# AC7840x register map
Vendor: AutoChips; Series: AC78; File version: 1.0
CPU: CM4 r0p1, little endian, MPU, FPU, VTOR, 4 interrupt priority bits
Registers are 32-bit, read-write, reset 0x0 unless marked. A register's access mark holds for its fields unless they carry their own. Offsets are from the block's base; [hi:lo] are bit positions; lines under a group give offsets from that group; {n}, {i} and the like mark numbered series; 'fields as' and 'values as' point back to an identical list.

## ADC0 — Analog to Digital Converter
Base 0x40003000
Same registers: ADC1 0x40004000
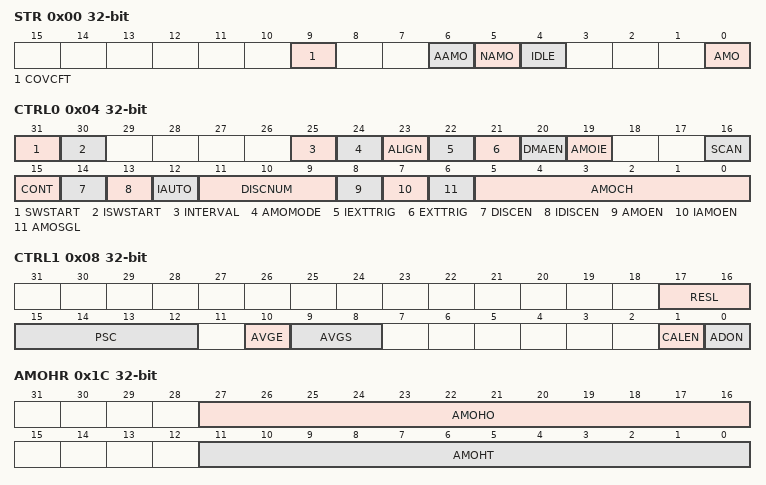
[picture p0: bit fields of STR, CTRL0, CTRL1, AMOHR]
0x00 STR — ADC status Register
  [9] COVCFT — Convert trigger confilict status
    0=No conflict; 1=Conflict occurred
  [6] AAMO — Analog monitor Abnormal event occurs(Edge mode)
    0=No analog monitor event; 1=Analog monitor abnormal event occurs
  [5] NAMO — Analog monitor normal event occurs(Edge mode)
    0=No analog monitor event; 1=Analog monitor normal event occurs
  [4] IDLE ro — ADC idle status indicate
    0=Busy status; 1=Idle status
  [0] AMO — Analog monitor event occurs(Level mode)
    0=No analog monitor event; 1=Analog monitor event occurs
0x04 CTRL0 — ADC Control Register 0
  [31] SWSTART — Software trigger for regular group
  [30] ISWSTART — Software trigger for Inject group
  [25] INTERVAL — Interval mode
    0=Normal mode; 1=Interval mode
  [24] AMOMODE — Analog monitor type
    0=Level mode; 1=Edge mode
  [23] ALIGN — Data Alignment
    0=Right Alignment; 1=Left Alignment
  [22] IEXTTRIG — Injected group trigger source select
    0=Internal trigger source; 1=External trigger source
  [21] EXTTRIG — Regular group trigger source select
    0=Internal trigger source; 1=External trigger source
  [20] DMAEN — DMA Function Enable
    0=DMA function disabled; 1=DMA function enabled
  [19] AMOIE — AMO interrupt Enable
    0=AMO interrupt disabled; 1=AMO interrupt enabled
  [16] SCAN — Scan Mode
    0=Scan mode disabled; 1=Scan mode enabled
  [15] CONT — Continuous conversion
    0=Single conversion mode; 1=Continuous conversion mode
  [14] DISCEN — Discontinous mode on regular group
    0=Regular group Discontinous mode disabled; 1=Regular group Discontinous mode enabled
  [13] IDISCEN — Discontinous mode on injected group
    0=Injected group Discontinous mode disabled; 1=Injected group Discontinous mode enabled
  [12] IAUTO — Injected Group Automatic Conversion
    0=Injected group automatic conversion disabled; 1=Injected group automatic conversion enabled
  [11:9] DISCNUM — Discontinuous conversion length of Regular Group
  [8] AMOEN — Regular Group Analog Monitor Detect function Enable
  [7] IAMOEN — Injected Group Analog Monitor Detect function Enable
  [6] AMOSGL — Analog monitor detecting channel
    0=AMO used in All channels; 1=AMO function used in single channel defined in AMOCH register
  [5:0] AMOCH — Analog monitor detecting channel
0x08 CTRL1 — ADC Control Register 1
  [17:16] RESL — Resolution selection
    0=12-bit resolution; 1=10-bit resolution; 2=8-bit resolution
  [15:12] PSC — Input clock prescaler
    {v}=Divide by {v+1} (v=0..15)
  [10] AVGE — Hardware Average Enable
    0=Hardware average function disabled; 1=Hardware average function enabled
  [9:8] AVGS — Hardware Average Select
    0=4 samples averaged; 1=8 samples averaged; 2=16 samples averaged; 3=32 samples averaged
  [1] CALEN — Calibration
    0=Disable Calibration; 1=Enable Calibration
  [0] ADON — ADC converter power
    0=ADC converter power off; 1=ADC converter power on
{0xC+4i} IOFR{i} (i=0..3) — ADC Injected Group Offset Register(n)
  [11:0] IOFR — Injected group offset Value
0x1C AMOHR — AMO High threshold and offset register
  [27:16] AMOHO — High offset value
  [11:0] AMOHT — AMO High threshold value
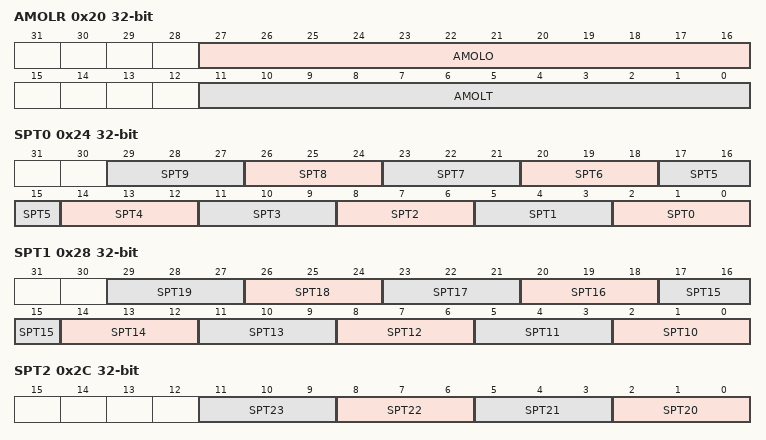
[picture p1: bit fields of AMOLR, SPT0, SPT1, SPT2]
0x20 AMOLR — AMO Low threshold and offset register
  [27:16] AMOLO — Low offset value
  [11:0] AMOLT — AMO Low threshold value
0x24 SPT0 — ADC Sample time setting register 0
  [all] fields
    0=5 ADCCLK; 1=10 ADCCLK; 2=15 ADCCLK; 3=23 ADCCLK; 4=35 ADCCLK; 5=45 ADCCLK; 6=85 ADCCLK; 7=185 ADCCLK
  [3n+2:3n] SPT{n} (n=0..9) — Sample time for channel {n}
0x28 SPT1 — ADC Sample time setting register 1
  [all] fields
    values as the fields of SPT0
  [3n-28:3n-30] SPT{n} (n=10..19) — Sample time for channel {n}
0x2C SPT2 — ADC Sample time setting register 2
  [all] fields
    values as the fields of SPT0
  [3n-58:3n-60] SPT{n} (n=20..23) — Sample time for channel {n}
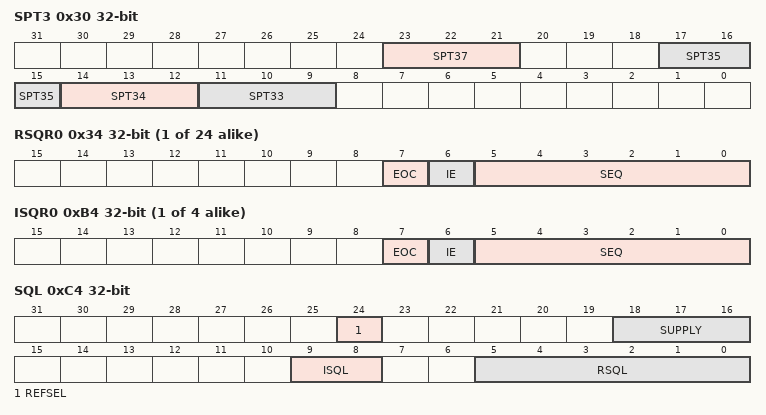
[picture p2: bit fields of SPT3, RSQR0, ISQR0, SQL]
0x30 SPT3 — ADC Sample time setting register 3
  [all] fields
    values as the fields of SPT0
  [23:21] SPT37 — Sample time for channel 37
  [17:15] SPT35 — Sample time for channel 35
  [14:12] SPT34 — Sample time for channel 34
  [11:9] SPT33 — Sample time for channel 33
{0x34+4i} RSQR{i} (i=0..23) — ADC regular group sequence configure register(n)
  [7] EOC ro — End of conversion flag
    0=Conversion is not completed; 1=Conversion is completed
  [6] IE — Interrupt enable
    0=Conversion complete interrupt is disabled; 1=Conversion complete interrupt is enabled
  [5:0] SEQ — Channel selection for regular group
    {v}=Exernal channel {v} is selected as input (v=0..23); 33=BandGap channel is selected as input; 34=T-sensor channel is selected as input; 35=GEOE calibration channel is selected as input; 37=Power supply channel is selected as input; 63=Channel disabled
{0xB4+4i} ISQR{i} (i=0..3) — ADC injected group sequence configure register(n)
  [7] EOC ro — End of conversion flag
    0=Conversion is not completed; 1=Conversion is completed
  [6] IE — Interrupt enable
    values as RSQR0.IE
  [5:0] SEQ — Channel selection for injected group
    values as RSQR0.SEQ
0xC4 SQL — Sequence length of group configure register
  [24] REFSEL — Voltage reference selection
    0=Voltage reference pin pair VREFH and VREFL; 1=Voltage reference analog supply (VDDA)
  [18:16] SUPPLY — Internal supply selection
    0=input VDD supply (VDD); 1=input analog supply (VDDA); 2=ADC Reference Supply (VREFH); 3=Oscillator Regulator Output; 4=Flash regulator output; 5=Digital regulator output
  [9:8] ISQL — Sequence length of injected group
  [5:0] RSQL — Sequence length of regular group
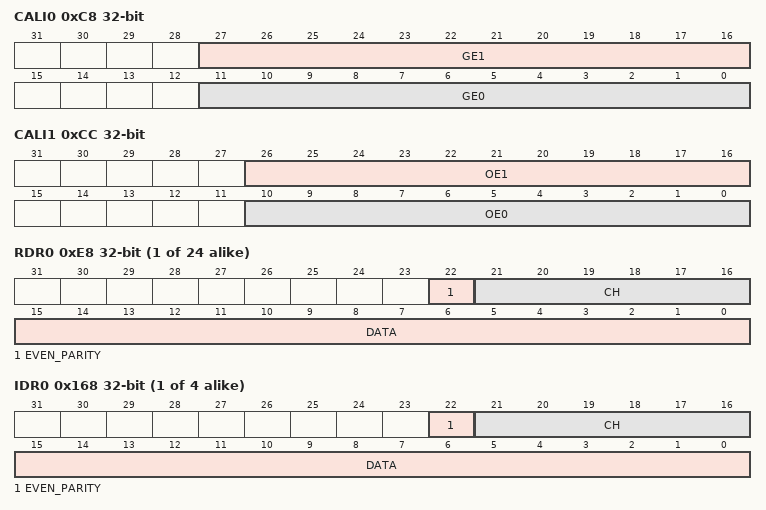
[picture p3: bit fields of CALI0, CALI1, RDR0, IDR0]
0xC8 CALI0 — ADC Calibration Register 0
  [27:16] GE1 — Gain error adjustment factor 1
  [11:0] GE0 — Gain error adjustment factor 0
0xCC CALI1 — ADC Calibration Register 1
  [26:16] OE1 — Offset error adjustment factor 1
  [10:0] OE0 — Gain error adjustment factor 0
{0xE8+4i} RDR{i} (i=0..23) ro — ADC Regular Group data Register(n)
  [22] EVEN_PARITY — Even Parity Check
  [21:16] CH — Channel Number
  [15:0] DATA — Data Value for regular group
{0x168+4i} IDR{i} (i=0..3) ro — ADC Injected Group data Register(n)
  [22] EVEN_PARITY — Even Parity Check
  [21:16] CH — Channel Number
  [15:0] DATA — Data Value for inject group
